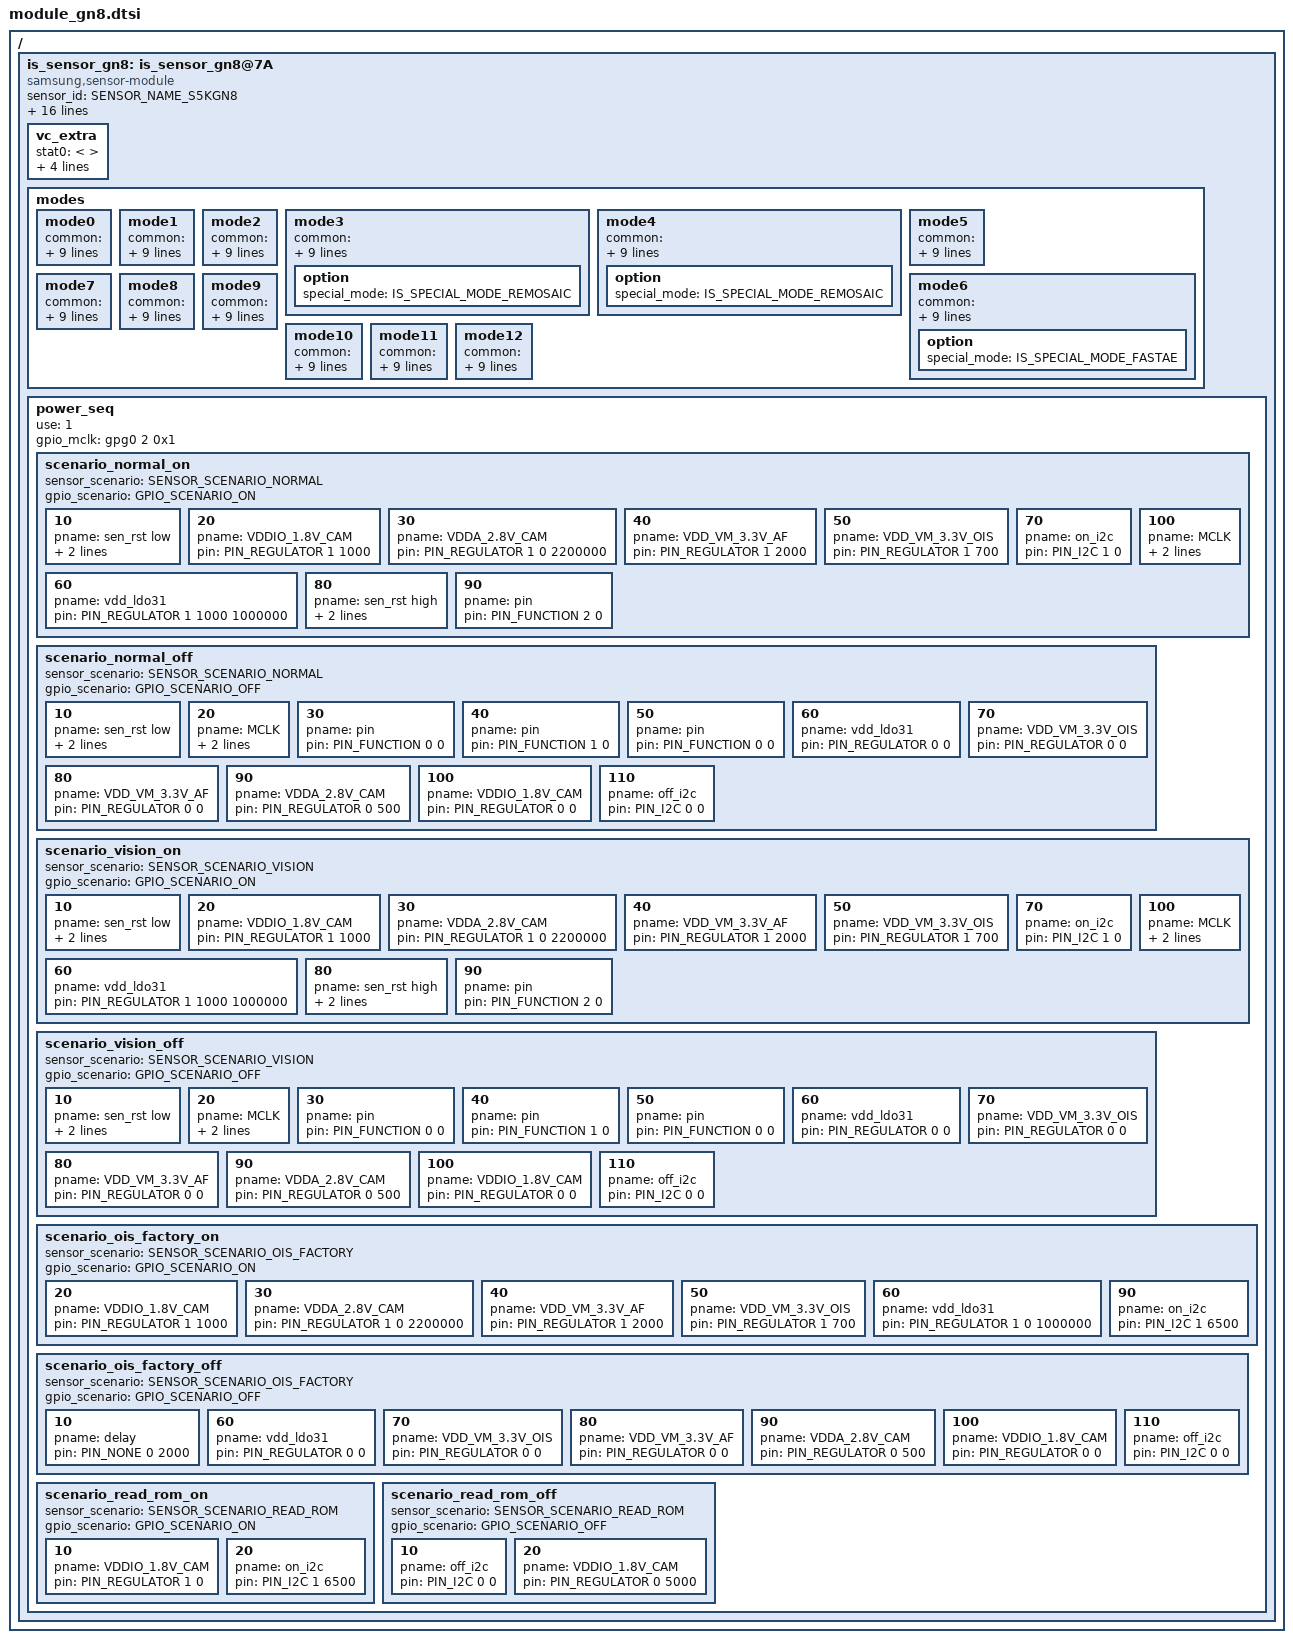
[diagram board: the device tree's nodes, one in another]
/*
 * SAMSUNG EXYNOSxxxx board camera device tree source
 *
 * Copyright (c) 2023 Samsung Electronics Co., Ltd.
 *		http://www.samsung.com
 *
 * This program is free software; you can redistribute it and/or modify
 * it under the terms of the GNU General Public License version 2 as
 * published by the Free Software Foundation.
 */

#include <dt-bindings/camera/exynos_is_dt.h>

/ {
	fragment@camera {
		target-path = "/";
		__overlay__ {
			is_sensor_gn8: is_sensor_gn8@7A {
				compatible = "samsung,sensor-module";

				sensor_id = <SENSOR_NAME_S5KGN8>;
				active_width = <8160>;
				active_height = <6120>;
				margin_left = <0>;
				margin_right = <0>;
				margin_top = <0>;
				margin_bottom = <0>;
				max_framerate = <480>;
				bitwidth = <10>;
				use_retention_mode = <SENSOR_RETENTION_UNSUPPORTED>;
				sensor_maker = "SLSI";
				sensor_name = "S5KGN8";
				setfile_name = "setfile_gn8.bin";

				status = "okay";

				/* vendor */
				rom_type = <2>; /* ROM_TYPE_EEPROM */
				rom_id = <0>;
				rom_cal_index = <0>;

				vc_extra {
					/* ex) statX = <stat_type, sensor_mode, max_width, max_height, max_element> */
					stat0 = </* not available */>;									/* VC_BUF_DATA_TYPE_SENSOR_STAT1 */
					stat1 = </*VC_STAT_TYPE_PDP_4_1_PDAF_STAT0*/ 1200 /*VC_SENSOR_MODE_2PD_MODE3*/ 102 4080 764 2>;	/* VC_BUF_DATA_TYPE_GENERAL_STAT1 */
					stat2 = </* not available */>;									/* VC_BUF_DATA_TYPE_SENSOR_STAT2 */
					stat3 = </*VC_STAT_TYPE_PDP_4_1_PDAF_STAT1*/ 1201 /*VC_SENSOR_MODE_2PD_MODE3*/ 102 4080 764 2>;	/* VC_BUF_DATA_TYPE_GENERAL_STAT2 */
					stat_vc = <2>; /* STAT out VC after CSIS link */
				};


				modes {
					/* common = <width, height, fps, settle, mode, lane, speed, interleave, lrte, pd_mode> */
					/* vcX = <map, hwformat, width, height, hwformat, type, width, height> */

					mode0 {
						common = <4080 3060 30 0 0 CSI_DATA_LANES_3 2379 CSI_MODE_VC_DT LRTE_ENABLE PD_MOD3 EX_NONE>;
						vc0 = </* in */ 0 HW_FORMAT_RAW10 4080 3060    /* out */ HW_FORMAT_RAW10 VC_NOTHING 4080 3060>;
						vc1 = </* in */ 2 HW_FORMAT_UNKNOWN 0 0        /* out */ HW_FORMAT_UNKNOWN VC_NOTHING 0 0>;
						vc2 = </* in */ 1 HW_FORMAT_RAW10_POTF 4080 764  /* out */ HW_FORMAT_RAW10 VC_NOTHING 0 0>;
						vc3 = </* in */ 3 HW_FORMAT_UNKNOWN 0 0        /* out */ HW_FORMAT_UNKNOWN VC_NOTHING 0 0>;
					};
					mode1 {
						common = <4080 2296 30 0 1 CSI_DATA_LANES_3 2379 CSI_MODE_VC_DT LRTE_ENABLE PD_MOD3 EX_NONE>;
						vc0 = </* in */ 0 HW_FORMAT_RAW10 4080 2296    /* out */ HW_FORMAT_RAW10 VC_NOTHING 4080 2296>;
						vc1 = </* in */ 2 HW_FORMAT_UNKNOWN 0 0        /* out */ HW_FORMAT_UNKNOWN VC_NOTHING 0 0>;
						vc2 = </* in */ 1 HW_FORMAT_RAW10_POTF 4080 574  /* out */ HW_FORMAT_RAW10 VC_NOTHING 0 0>;
						vc3 = </* in */ 3 HW_FORMAT_UNKNOWN 0 0        /* out */ HW_FORMAT_UNKNOWN VC_NOTHING 0 0>;
					};
					mode2 {
						common = <4080 2296 60 0 2 CSI_DATA_LANES_3 2379 CSI_MODE_VC_DT LRTE_ENABLE PD_MOD3 EX_NONE>;
						vc0 = </* in */ 0 HW_FORMAT_RAW10 4080 2296    /* out */ HW_FORMAT_RAW10 VC_NOTHING 4080 2296>;
						vc1 = </* in */ 2 HW_FORMAT_UNKNOWN 0 0        /* out */ HW_FORMAT_UNKNOWN VC_NOTHING 0 0>;
						vc2 = </* in */ 1 HW_FORMAT_RAW10_POTF 4080 574  /* out */ HW_FORMAT_RAW10 VC_NOTHING 0 0>;
						vc3 = </* in */ 3 HW_FORMAT_UNKNOWN 0 0        /* out */ HW_FORMAT_UNKNOWN VC_NOTHING 0 0>;
					};
					mode3 {
						common = <8160 6120 15 0 3 CSI_DATA_LANES_3 2379 CSI_MODE_VC_DT LRTE_ENABLE PD_NONE EX_NONE>;
						vc0 = </* in */ 0 HW_FORMAT_RAW10 8160 6120    /* out */ HW_FORMAT_RAW10 VC_NOTHING 8160 6120>;
						vc1 = </* in */ 1 HW_FORMAT_UNKNOWN 0 0        /* out */ HW_FORMAT_UNKNOWN VC_NOTHING 0 0>;
						vc2 = </* in */ 2 HW_FORMAT_UNKNOWN 0 0        /* out */ HW_FORMAT_UNKNOWN VC_NOTHING 0 0>;
						vc3 = </* in */ 3 HW_FORMAT_UNKNOWN 0 0        /* out */ HW_FORMAT_UNKNOWN VC_NOTHING 0 0>;
						option { special_mode = <IS_SPECIAL_MODE_REMOSAIC>; };
					};
					mode4 {
						common = <8160 4592 15 0 4 CSI_DATA_LANES_3 2379 CSI_MODE_VC_DT LRTE_ENABLE PD_NONE EX_NONE>;
						vc0 = </* in */ 0 HW_FORMAT_RAW10 8160 4592    /* out */ HW_FORMAT_RAW10 VC_NOTHING 8160 4592>;
						vc1 = </* in */ 1 HW_FORMAT_UNKNOWN 0 0        /* out */ HW_FORMAT_UNKNOWN VC_NOTHING 0 0>;
						vc2 = </* in */ 2 HW_FORMAT_UNKNOWN 0 0        /* out */ HW_FORMAT_UNKNOWN VC_NOTHING 0 0>;
						vc3 = </* in */ 3 HW_FORMAT_UNKNOWN 0 0        /* out */ HW_FORMAT_UNKNOWN VC_NOTHING 0 0>;
						option { special_mode = <IS_SPECIAL_MODE_REMOSAIC>; };
					};
					mode5 {
						common = <2040 1532 30 0 5 CSI_DATA_LANES_3 1436 CSI_MODE_VC_DT LRTE_ENABLE PD_NONE EX_NONE>;
						vc0 = </* in */ 0 HW_FORMAT_RAW10 2040 1532    /* out */ HW_FORMAT_RAW10 VC_NOTHING 2040 1532>;
						vc1 = </* in */ 1 HW_FORMAT_UNKNOWN 0 0        /* out */ HW_FORMAT_UNKNOWN VC_NOTHING 0 0>;
						vc2 = </* in */ 2 HW_FORMAT_UNKNOWN 0 0        /* out */ HW_FORMAT_UNKNOWN VC_NOTHING 0 0>;
						vc3 = </* in */ 3 HW_FORMAT_UNKNOWN 0 0        /* out */ HW_FORMAT_UNKNOWN VC_NOTHING 0 0>;
					};
					mode6 {
						common = <2040 1532 120 0 6 CSI_DATA_LANES_3 1436 CSI_MODE_VC_DT LRTE_ENABLE PD_NONE EX_NONE>;
						vc0 = </* in */ 0 HW_FORMAT_RAW10 2040 1532    /* out */ HW_FORMAT_RAW10 VC_NOTHING 2040 1532>;
						vc1 = </* in */ 1 HW_FORMAT_UNKNOWN 0 0        /* out */ HW_FORMAT_UNKNOWN VC_NOTHING 0 0>;
						vc2 = </* in */ 2 HW_FORMAT_UNKNOWN 0 0        /* out */ HW_FORMAT_UNKNOWN VC_NOTHING 0 0>;
						vc3 = </* in */ 3 HW_FORMAT_UNKNOWN 0 0        /* out */ HW_FORMAT_UNKNOWN VC_NOTHING 0 0>;
						option { special_mode = <IS_SPECIAL_MODE_FASTAE>; };
					};
					mode7 {
						common = <2040 1148 120 0 7 CSI_DATA_LANES_3 1436 CSI_MODE_VC_DT LRTE_ENABLE PD_NONE EX_NONE>;
						vc0 = </* in */ 0 HW_FORMAT_RAW10 2040 1148    /* out */ HW_FORMAT_RAW10 VC_NOTHING 2040 1148>;
						vc1 = </* in */ 1 HW_FORMAT_UNKNOWN 0 0        /* out */ HW_FORMAT_UNKNOWN VC_NOTHING 0 0>;
						vc2 = </* in */ 2 HW_FORMAT_UNKNOWN 0 0        /* out */ HW_FORMAT_UNKNOWN VC_NOTHING 0 0>;
						vc3 = </* in */ 3 HW_FORMAT_UNKNOWN 0 0        /* out */ HW_FORMAT_UNKNOWN VC_NOTHING 0 0>;
					};
					mode8 {
						common = <2040 1148 240 0 8 CSI_DATA_LANES_3 1436 CSI_MODE_VC_ONLY LRTE_ENABLE PD_NONE EX_NONE>;
						vc0 = </* in */ 0 HW_FORMAT_RAW10 2040 1148    /* out */ HW_FORMAT_RAW10 VC_NOTHING 2040 1148>;
						vc1 = </* in */ 1 HW_FORMAT_UNKNOWN 0 0        /* out */ HW_FORMAT_UNKNOWN VC_NOTHING 0 0>;
						vc2 = </* in */ 2 HW_FORMAT_UNKNOWN 0 0        /* out */ HW_FORMAT_UNKNOWN VC_NOTHING 0 0>;
						vc3 = </* in */ 3 HW_FORMAT_UNKNOWN 0 0        /* out */ HW_FORMAT_UNKNOWN VC_NOTHING 0 0>;
					};
					mode9 {
						common = <4080 3060 30 0 13 CSI_DATA_LANES_3 2379 CSI_MODE_VC_DT LRTE_ENABLE PD_MOD3 EX_NONE>;
						vc0 = </* in */ 0 HW_FORMAT_RAW12 4080 3060    /* out */ HW_FORMAT_RAW12 VC_NOTHING 4080 3060>;
						vc1 = </* in */ 2 HW_FORMAT_UNKNOWN 0 0        /* out */ HW_FORMAT_UNKNOWN VC_NOTHING 0 0>;
						vc2 = </* in */ 1 HW_FORMAT_RAW10_POTF 4080 764  /* out */ HW_FORMAT_RAW10 VC_NOTHING 0 0>;
						vc3 = </* in */ 3 HW_FORMAT_UNKNOWN 0 0        /* out */ HW_FORMAT_UNKNOWN VC_NOTHING 0 0>;
					};
					mode10 {
						common = <4080 2296 30 0 14 CSI_DATA_LANES_3 1436 CSI_MODE_VC_DT LRTE_ENABLE PD_MOD3 EX_NONE>;
						vc0 = </* in */ 0 HW_FORMAT_RAW12 4080 2296    /* out */ HW_FORMAT_RAW12 VC_NOTHING 4080 2296>;
						vc1 = </* in */ 2 HW_FORMAT_UNKNOWN 0 0        /* out */ HW_FORMAT_UNKNOWN VC_NOTHING 0 0>;
						vc2 = </* in */ 1 HW_FORMAT_RAW10_POTF 4080 574     /* out */ HW_FORMAT_RAW10 VC_NOTHING 0 0>;
						vc3 = </* in */ 3 HW_FORMAT_UNKNOWN 0 0        /* out */ HW_FORMAT_UNKNOWN VC_NOTHING 0 0>;
					};
					mode11 {
						common = <4080 3060 15 0 15 CSI_DATA_LANES_3 2379 CSI_MODE_VC_DT LRTE_ENABLE PD_MOD3 EX_NONE>;
						vc0 = </* in */ 0 HW_FORMAT_RAW10 4080 3060    /* out */ HW_FORMAT_RAW10 VC_NOTHING 4080 3060>;
						vc1 = </* in */ 2 HW_FORMAT_UNKNOWN 0 0        /* out */ HW_FORMAT_UNKNOWN VC_NOTHING 0 0>;
						vc2 = </* in */ 1 HW_FORMAT_RAW10_POTF 4080 764  /* out */ HW_FORMAT_RAW10 VC_NOTHING 0 0>;
						vc3 = </* in */ 3 HW_FORMAT_UNKNOWN 0 0        /* out */ HW_FORMAT_UNKNOWN VC_NOTHING 0 0>;
					};
					mode12 {
						common = <4080 2296 15 0 16 CSI_DATA_LANES_3 2379 CSI_MODE_VC_DT LRTE_ENABLE PD_MOD3 EX_NONE>;
						vc0 = </* in */ 0 HW_FORMAT_RAW10 4080 2296    /* out */ HW_FORMAT_RAW10 VC_NOTHING 4080 2296>;
						vc1 = </* in */ 2 HW_FORMAT_UNKNOWN 0 0        /* out */ HW_FORMAT_UNKNOWN VC_NOTHING 0 0>;
						vc2 = </* in */ 1 HW_FORMAT_RAW10_POTF 4080 574     /* out */ HW_FORMAT_RAW10 VC_NOTHING 0 0>;
						vc3 = </* in */ 3 HW_FORMAT_UNKNOWN 0 0        /* out */ HW_FORMAT_UNKNOWN VC_NOTHING 0 0>;
					};
				};

				power_seq {
					use = <1>;
					gpio_mclk = <&gpg0 2 0x1>;

					scenario_normal_on {
						sensor_scenario = <SENSOR_SCENARIO_NORMAL>;
						gpio_scenario = <GPIO_SCENARIO_ON>;

						/* A start node number should be over the 10 for reserved number 0~9. */
						/* pname = "name"; pin = <act value delay voltage>; gpio = <gpx# # 0x1>; */
						10 { pname = "sen_rst low"; pin = <PIN_OUTPUT 0 500>; gpio = <&gpg1 1 0x1>; };
						20 { pname = "VDDIO_1.8V_CAM"; pin = <PIN_REGULATOR 1 1000>; };
						30 { pname = "VDDA_2.8V_CAM"; pin = <PIN_REGULATOR 1 0 2200000>; };
						40 { pname = "VDD_VM_3.3V_AF"; pin = <PIN_REGULATOR 1 2000>; };
						50 { pname = "VDD_VM_3.3V_OIS"; pin = <PIN_REGULATOR 1 700>; };
						60 { pname = "vdd_ldo31"; pin = <PIN_REGULATOR 1 1000 1000000>; };
						70 { pname = "on_i2c"; pin = <PIN_I2C 1 0>; };
						80 { pname = "sen_rst high"; pin = <PIN_OUTPUT 1 0>; gpio = <&gpg1 1 0x1>; };
						90 { pname = "pin"; pin = <PIN_FUNCTION 2 0>; };
						100 { pname = "MCLK"; pin = <PIN_MCLK 1 10000>; gpio = <&gpg0 2 0x1>; };
					};

					scenario_normal_off {
						sensor_scenario = <SENSOR_SCENARIO_NORMAL>;
						gpio_scenario = <GPIO_SCENARIO_OFF>;

						/* A start node number should be over the 10 for reserved number 0~9. */
						/* pname = "name"; pin = <act value delay voltage>; gpio = <gpx# # 0x1>; */
						10 { pname = "sen_rst low"; pin = <PIN_OUTPUT 0 500>; gpio = <&gpg1 1 0x1>; };
						20 { pname = "MCLK"; pin = <PIN_MCLK 0 500>; gpio = <&gpg0 2 0x1>; };
						30 { pname = "pin"; pin = <PIN_FUNCTION 0 0>; };
						40 { pname = "pin"; pin = <PIN_FUNCTION 1 0>; };
						50 { pname = "pin"; pin = <PIN_FUNCTION 0 0>; };
						60 { pname = "vdd_ldo31"; pin = <PIN_REGULATOR 0 0>; };
						70 { pname = "VDD_VM_3.3V_OIS"; pin = <PIN_REGULATOR 0 0>; };
						80 { pname = "VDD_VM_3.3V_AF"; pin = <PIN_REGULATOR 0 0>; };
						90 { pname = "VDDA_2.8V_CAM"; pin = <PIN_REGULATOR 0 500>; };
						100 { pname = "VDDIO_1.8V_CAM"; pin = <PIN_REGULATOR 0 0>; };
						110 { pname = "off_i2c"; pin = <PIN_I2C 0 0>; };
					};

					scenario_vision_on {
						sensor_scenario = <SENSOR_SCENARIO_VISION>;
						gpio_scenario = <GPIO_SCENARIO_ON>;

						/* A start node number should be over the 10 for reserved number 0~9. */
						/* pname = "name"; pin = <act value delay voltage>; gpio = <gpx# # 0x1>; */
						10 { pname = "sen_rst low"; pin = <PIN_OUTPUT 0 500>; gpio = <&gpg1 1 0x1>; };
						20 { pname = "VDDIO_1.8V_CAM"; pin = <PIN_REGULATOR 1 1000>; };
						30 { pname = "VDDA_2.8V_CAM"; pin = <PIN_REGULATOR 1 0 2200000>; };
						40 { pname = "VDD_VM_3.3V_AF"; pin = <PIN_REGULATOR 1 2000>; };
						50 { pname = "VDD_VM_3.3V_OIS"; pin = <PIN_REGULATOR 1 700>; };
						60 { pname = "vdd_ldo31"; pin = <PIN_REGULATOR 1 1000 1000000>; };
						70 { pname = "on_i2c"; pin = <PIN_I2C 1 0>; };
						80 { pname = "sen_rst high"; pin = <PIN_OUTPUT 1 0>; gpio = <&gpg1 1 0x1>; };
						90 { pname = "pin"; pin = <PIN_FUNCTION 2 0>; };
						100 { pname = "MCLK"; pin = <PIN_MCLK 1 10000>; gpio = <&gpg0 2 0x1>; };
					};

					scenario_vision_off {
						sensor_scenario = <SENSOR_SCENARIO_VISION>;
						gpio_scenario = <GPIO_SCENARIO_OFF>;

						/* A start node number should be over the 10 for reserved number 0~9. */
						/* pname = "name"; pin = <act value delay voltage>; gpio = <gpx# # 0x1>; */
						10 { pname = "sen_rst low"; pin = <PIN_OUTPUT 0 500>; gpio = <&gpg1 1 0x1>; };
						20 { pname = "MCLK"; pin = <PIN_MCLK 0 500>; gpio = <&gpg0 2 0x1>; };
						30 { pname = "pin"; pin = <PIN_FUNCTION 0 0>; };
						40 { pname = "pin"; pin = <PIN_FUNCTION 1 0>; };
						50 { pname = "pin"; pin = <PIN_FUNCTION 0 0>; };
						60 { pname = "vdd_ldo31"; pin = <PIN_REGULATOR 0 0>; };
						70 { pname = "VDD_VM_3.3V_OIS"; pin = <PIN_REGULATOR 0 0>; };
						80 { pname = "VDD_VM_3.3V_AF"; pin = <PIN_REGULATOR 0 0>; };
						90 { pname = "VDDA_2.8V_CAM"; pin = <PIN_REGULATOR 0 500>; };
						100 { pname = "VDDIO_1.8V_CAM"; pin = <PIN_REGULATOR 0 0>; };
						110 { pname = "off_i2c"; pin = <PIN_I2C 0 0>; };
					};

					scenario_ois_factory_on {
						sensor_scenario = <SENSOR_SCENARIO_OIS_FACTORY>;
						gpio_scenario = <GPIO_SCENARIO_ON>;

						/* A start node number should be over the 10 for reserved number 0~9. */
						/* pname = "name"; pin = <act value delay voltage>; gpio = <gpx# # 0x1>; */
						20 { pname = "VDDIO_1.8V_CAM"; pin = <PIN_REGULATOR 1 1000>; };
						30 { pname = "VDDA_2.8V_CAM"; pin = <PIN_REGULATOR 1 0 2200000>; };
						40 { pname = "VDD_VM_3.3V_AF"; pin = <PIN_REGULATOR 1 2000>; };
						50 { pname = "VDD_VM_3.3V_OIS"; pin = <PIN_REGULATOR 1 700>; };
						60 { pname = "vdd_ldo31"; pin = <PIN_REGULATOR 1 0 1000000>; };
						90 { pname = "on_i2c"; pin = <PIN_I2C 1 6500>; };
					};

					scenario_ois_factory_off {
						sensor_scenario = <SENSOR_SCENARIO_OIS_FACTORY>;
						gpio_scenario = <GPIO_SCENARIO_OFF>;

						/* A start node number should be over the 10 for reserved number 0~9. */
						/* pname = "name"; pin = <act value delay voltage>; gpio = <gpx# # 0x1>; */
						10 { pname = "delay"; pin = <PIN_NONE 0 2000>; };
						60 { pname = "vdd_ldo31"; pin = <PIN_REGULATOR 0 0>; };
						70 { pname = "VDD_VM_3.3V_OIS"; pin = <PIN_REGULATOR 0 0>; };
						80 { pname = "VDD_VM_3.3V_AF"; pin = <PIN_REGULATOR 0 0>; };
						90 { pname = "VDDA_2.8V_CAM"; pin = <PIN_REGULATOR 0 500>; };
						100 { pname = "VDDIO_1.8V_CAM"; pin = <PIN_REGULATOR 0 0>; };
						110 { pname = "off_i2c"; pin = <PIN_I2C 0 0>; };
					};

					scenario_read_rom_on {
						sensor_scenario = <SENSOR_SCENARIO_READ_ROM>;
						gpio_scenario = <GPIO_SCENARIO_ON>;

						/* A start node number should be over the 10 for reserved number 0~9. */
						/* pname = "name"; pin = <act value delay voltage>; gpio = <gpx# # 0x1>; */
						10 { pname = "VDDIO_1.8V_CAM"; pin = <PIN_REGULATOR 1 0>; };
						20 { pname = "on_i2c"; pin = <PIN_I2C 1 6500>; };
					};

					scenario_read_rom_off {
						sensor_scenario = <SENSOR_SCENARIO_READ_ROM>;
						gpio_scenario = <GPIO_SCENARIO_OFF>;

						/* A start node number should be over the 10 for reserved number 0~9. */
						/* pname = "name"; pin = <act value delay voltage>; gpio = <gpx# # 0x1>; */
						10 { pname = "off_i2c"; pin = <PIN_I2C 0 0>; };
						20 { pname = "VDDIO_1.8V_CAM"; pin = <PIN_REGULATOR 0 5000>; };
					};
				};
			};
		}; /* end of __overlay__ */
	}; /* end of fragment */
}; /* end of root */
